VERSION ""

NS_ :

BS_:

BU_: XXX DSU HCU EPS IPAS XX

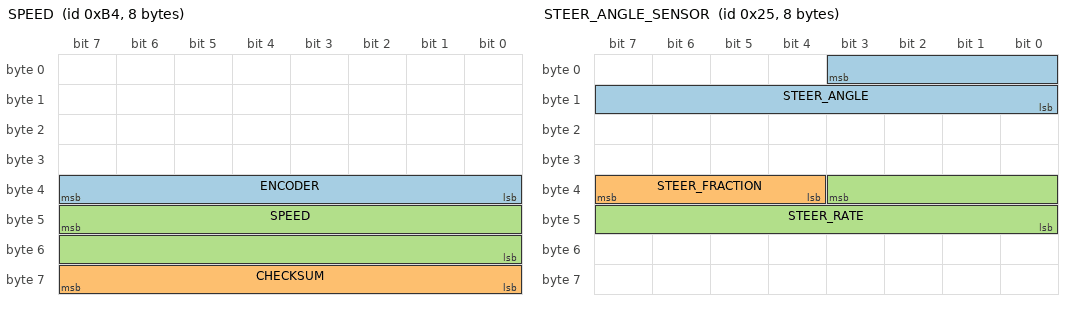
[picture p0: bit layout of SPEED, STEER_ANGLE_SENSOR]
BO_ 180 SPEED: 8 XXX
 SG_ ENCODER : 39|8@0+ (1,0) [0|255] "" XXX
 SG_ CHECKSUM : 63|8@0+ (1,0) [0|255] "" XXX
 SG_ SPEED : 47|16@0+ (0.01,0) [0|250] "kph" XXX

BO_ 560 BRAKE_MODULE2: 7 XXX
 SG_ BRAKE_PRESSED : 26|1@0+ (1,0) [0|1] "" XXX

BO_ 37 STEER_ANGLE_SENSOR: 8 XXX
 SG_ STEER_ANGLE : 3|12@0- (1.5,0) [-500|500] "deg" XXX
 SG_ STEER_FRACTION : 39|4@0- (0.1,0) [-0.7|0.7] "deg" XXX
 SG_ STEER_RATE : 35|12@0- (1,0) [-2000|2000] "deg/s" XXX

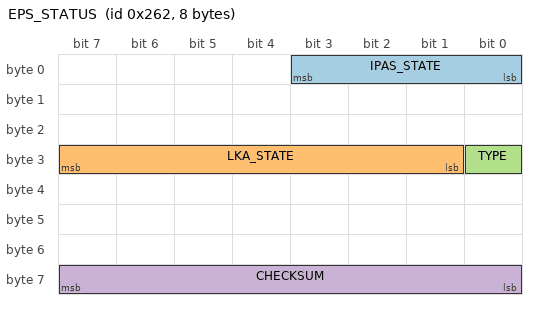
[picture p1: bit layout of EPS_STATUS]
BO_ 610 EPS_STATUS: 8 EPS
 SG_ IPAS_STATE : 3|4@0+ (1,0) [0|15] "" XXX
 SG_ LKA_STATE : 31|7@0+ (1,0) [0|127] "" XXX
 SG_ TYPE : 24|1@0+ (1,0) [0|1] "" XXX
 SG_ CHECKSUM : 63|8@0+ (1,0) [0|255] "" XXX

BO_ 177 SPEED_1: 8 XXX
 SG_ SPEED : 7|16@0+ (1,0) [0|250] "" XXX
 SG_ CHECKSUM : 40|8@1+ (1,0) [0|255] "" XXX

BO_ 179 SPEED_2: 8 XXX
 SG_ SPEED : 7|16@0+ (1,0) [0|255] "" XXX
 SG_ CHECKSUM : 47|8@0+ (1,0) [0|255] "" XXX

CM_ SG_ 560 BRAKE_PRESSED "another brake pressed?";
CM_ SG_ 37 STEER_FRACTION "1/15th of the signal STEER_ANGLE, which is 1.5 deg; note that 0x8 is never set";
CM_ SG_ 37 STEER_RATE "factor is tbd";
CM_ SG_ 610 TYPE "seems 1 on Corolla, 0 on all others";
VAL_ 610 IPAS_STATE 5 "override" 3 "enabled" 1 "disabled" ;
VAL_ 610 LKA_STATE 25 "temporary_fault" 9 "temporary_fault2" 5 "active" 1 "standby" ;
CM_ "AUTOGENERATED FILE, DO NOT EDIT"
CM_ "Imported file _comma.dbc starts her";
CM_ "Imported file _comma.dbc starts here
CM_ "Imported file _comma.dbc starts here";
CM_ "Imported file _comma.dbc starts here"
SG_ STATE : 7|4@0+ (1,0) [0|15] "" X";
CM_ "Imported file _toyota_2006.dbc starts here"
VERSION ";
CM_ "CHFFR_METRIC 37 STEER_ANGLE STEER_ANGLE 0.36 180";
CM_ "toyota_prius_2006_pt.dbc starts here"
